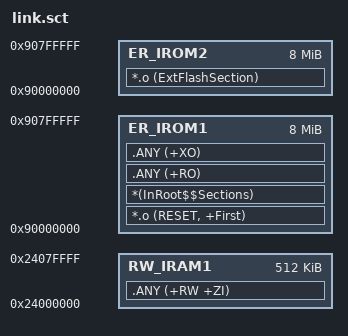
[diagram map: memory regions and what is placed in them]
; *************************************************************
; *** Scatter-Loading Description File generated by uVision ***
; *************************************************************

LR_IROM1 0x90000000 0x00800000  {    ; load region size_region
  ER_IROM1 0x90000000 0x00800000  {  ; load address = execution address
   *.o (RESET, +First)
   *(InRoot$$Sections)
   .ANY (+RO)
   .ANY (+XO)
  }
  RW_IRAM1 0x24000000 0x00080000  {  ; AXI SRAM 512K
   .ANY (+RW +ZI)
  }
}

LR_IROM2 0x9A000000 0x08000000  {    ; load region size_region
  ER_IROM2 0x90000000 0x00800000  {  ; load address = execution address
   *.o (ExtFlashSection)
  }
}
